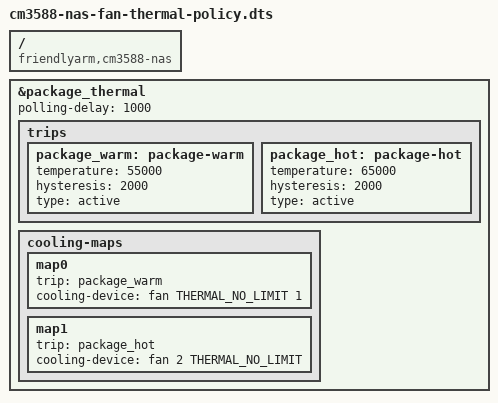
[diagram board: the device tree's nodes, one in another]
/dts-v1/;
/plugin/;

#include <dt-bindings/thermal/thermal.h>

/ {
	compatible = "friendlyarm,cm3588-nas",
		     "friendlyarm,cm3588",
		     "rockchip,rk3588";
};

&package_thermal {
	polling-delay = <1000>;

	trips {
		package_warm: package-warm {
			temperature = <55000>;
			hysteresis = <2000>;
			type = "active";
		};

		package_hot: package-hot {
			temperature = <65000>;
			hysteresis = <2000>;
			type = "active";
		};
	};

	cooling-maps {
		map0 {
			trip = <&package_warm>;
			cooling-device = <&fan THERMAL_NO_LIMIT 1>;
		};

		map1 {
			trip = <&package_hot>;
			cooling-device = <&fan 2 THERMAL_NO_LIMIT>;
		};
	};
};
